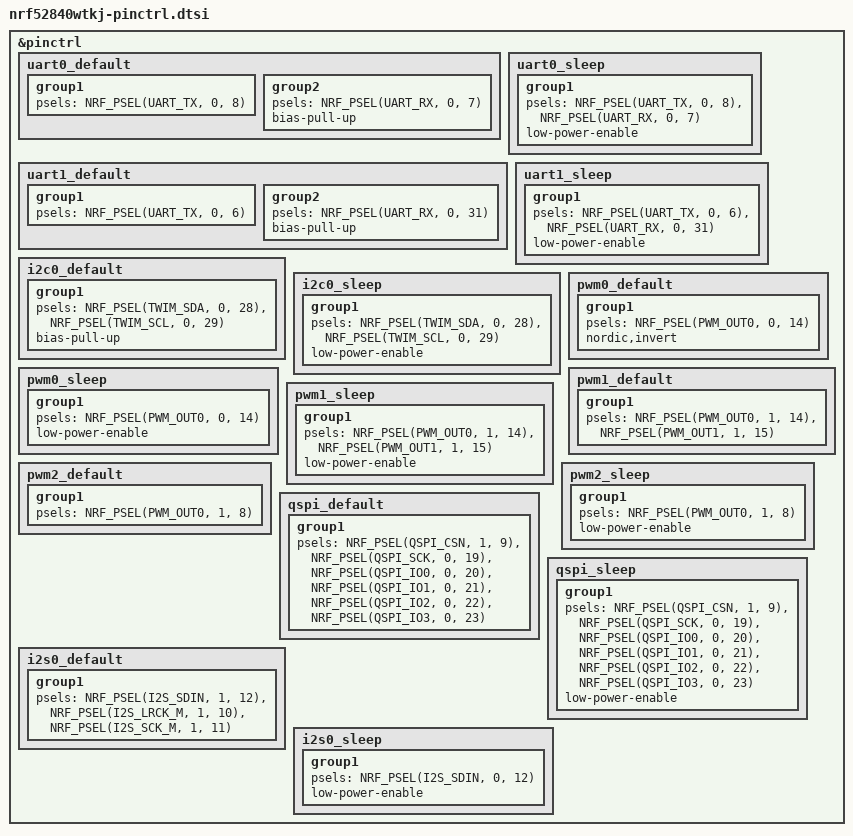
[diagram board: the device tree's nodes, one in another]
&pinctrl {
    uart0_default: uart0_default {
        group1 {
            psels = <NRF_PSEL(UART_TX, 0, 8)>;
        };
        group2 {
            psels = <NRF_PSEL(UART_RX, 0, 7)>;
            bias-pull-up;
        };
    };

    uart0_sleep: uart0_sleep {
        group1 {
            psels = <NRF_PSEL(UART_TX, 0, 8)>,
                    <NRF_PSEL(UART_RX, 0, 7)>;
            low-power-enable;
        };
    };

    uart1_default: uart1_default {
        group1 {
            psels = <NRF_PSEL(UART_TX, 0, 6)>;
        };
        group2 {
            psels = <NRF_PSEL(UART_RX, 0, 31)>;
            bias-pull-up;
        };
    };

    uart1_sleep: uart1_sleep {
        group1 {
            psels = <NRF_PSEL(UART_TX, 0, 6)>,
                    <NRF_PSEL(UART_RX, 0, 31)>;
            low-power-enable;
        };
    };

    i2c0_default: i2c0_default {
        group1 {
            psels = <NRF_PSEL(TWIM_SDA, 0, 28)>,
                    <NRF_PSEL(TWIM_SCL, 0, 29)>;
            bias-pull-up;
        };
    };

    i2c0_sleep: i2c0_sleep {
        group1 {
            psels = <NRF_PSEL(TWIM_SDA, 0, 28)>,
                    <NRF_PSEL(TWIM_SCL, 0, 29)>;
            low-power-enable;
        };
    };

    pwm0_default: pwm0_default {
        group1 {
            psels = <NRF_PSEL(PWM_OUT0, 0, 14)>;//配置输出通道0， 实际硬件上的p0.14引脚
            nordic,invert;//配置PWM输出信号反向（翻转高低电平）。
        };
    };

    pwm0_sleep: pwm0_sleep {
        group1 {
            psels = <NRF_PSEL(PWM_OUT0, 0, 14)>;

            low-power-enable;//低功耗模式，当设备进入睡眠状态时，切换到该配置，P0.14 引脚进入低功耗状态，降低待机功耗。
        };
    };

    pwm1_default: pwm1_default {
        group1 {
            psels = <NRF_PSEL(PWM_OUT0, 1, 14)>, //配置输出通道0， 实际硬件上的p1.14引脚
            <NRF_PSEL(PWM_OUT1, 1, 15)>;
        };
    };

    pwm1_sleep: pwm1_sleep {
        group1 {
            psels = <NRF_PSEL(PWM_OUT0, 1, 14)>,
                    <NRF_PSEL(PWM_OUT1, 1, 15)>;
            low-power-enable;//低功耗模式，当设备进入睡眠状态时，切换到该配置，P1.14 引脚进入低功耗状态，降低待机功耗。
        };
    };
    pwm2_default: pwm2_default {
        group1 {
            psels = <NRF_PSEL(PWM_OUT0, 1, 8)>; //配置输出通道0， 实际硬件上的p1.14引脚
        };
    };
    pwm2_sleep: pwm2_sleep {
        group1 {
            psels = <NRF_PSEL(PWM_OUT0, 1, 8)>;
            low-power-enable;//低功耗模式，当设备进入睡眠状态时，切换到该配置，P1.14 引脚进入低功耗状态，降低待机功耗。
        };
    };
    qspi_default: qspi_default {
        group1 {
            psels = <NRF_PSEL(QSPI_CSN, 1, 9)>,
                    <NRF_PSEL(QSPI_SCK, 0, 19)>,
                    <NRF_PSEL(QSPI_IO0, 0, 20)>,
                    <NRF_PSEL(QSPI_IO1, 0, 21)>,
                    <NRF_PSEL(QSPI_IO2, 0, 22)>,
                    <NRF_PSEL(QSPI_IO3, 0, 23)>;
        };
        
    };

    qspi_sleep: qspi_sleep {
        group1 {
            psels = <NRF_PSEL(QSPI_CSN, 1, 9)>,
                    <NRF_PSEL(QSPI_SCK, 0, 19)>,
                    <NRF_PSEL(QSPI_IO0, 0, 20)>,
                    <NRF_PSEL(QSPI_IO1, 0, 21)>,
                    <NRF_PSEL(QSPI_IO2, 0, 22)>,
                    <NRF_PSEL(QSPI_IO3, 0, 23)>;
            low-power-enable;
        };
    };

    i2s0_default: i2s0_default {
        group1 {
            psels = <NRF_PSEL(I2S_SDIN, 1, 12)>,
                    <NRF_PSEL(I2S_LRCK_M, 1, 10)>,
                    <NRF_PSEL(I2S_SCK_M, 1, 11)>;
        };
    };

    i2s0_sleep: i2s0_sleep {
        group1 {
            psels = <NRF_PSEL(I2S_SDIN, 0, 12)>;
            low-power-enable;
        };
    };
};
